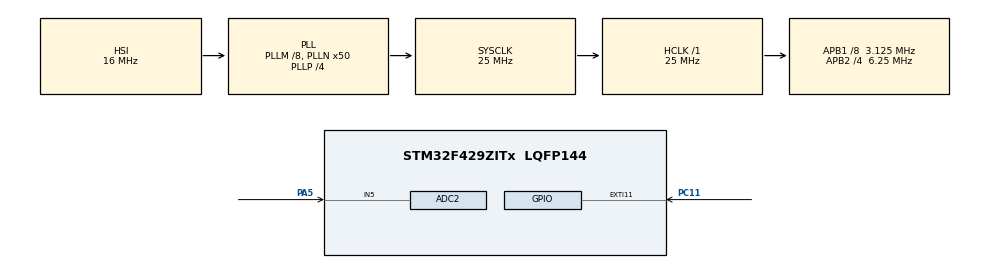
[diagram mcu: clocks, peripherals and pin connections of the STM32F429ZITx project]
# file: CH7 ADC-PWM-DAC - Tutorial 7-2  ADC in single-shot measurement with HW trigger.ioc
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ADC2.Channel-0\#ChannelRegularConversion=ADC_CHANNEL_5
ADC2.NbrOfConversionFlag=1
ADC2.Rank-0\#ChannelRegularConversion=1
ADC2.SamplingTime-0\#ChannelRegularConversion=ADC_SAMPLETIME_3CYCLES
Mcu.Family=STM32F4
Mcu.Name=STM32F429ZITx
Mcu.Package=LQFP144
NVIC.PriorityGroup=NVIC_PRIORITYGROUP_0
PA5.Signal=ADCx_IN5
PC11.Signal=GPXTI11
ProjectManager.HeapSize=0x200
ProjectManager.StackSize=0x400
ProjectManager.TargetToolchain=STM32CubeIDE
RCC.48MHZClocksFreq_Value=14285714.285714285
RCC.AHBFreq_Value=25000000
RCC.APB1CLKDivider=RCC_HCLK_DIV8
RCC.APB1Freq_Value=3125000
RCC.APB1TimFreq_Value=6250000
RCC.APB2CLKDivider=RCC_HCLK_DIV4
RCC.APB2Freq_Value=6250000
RCC.APB2TimFreq_Value=12500000
RCC.CortexFreq_Value=25000000
RCC.HCLKFreq_Value=25000000
RCC.HSE_VALUE=8000000
RCC.HSI_VALUE=16000000
RCC.LSE_VALUE=32768
RCC.PLLM=8
RCC.PLLN=50
RCC.PLLP=RCC_PLLP_DIV4
RCC.PLLQ=7
RCC.SYSCLKFreq_VALUE=25000000
RCC.SYSCLKSource=RCC_SYSCLKSOURCE_PLLCLK
RCC.VCOOutputFreq_Value=100000000
SH.ADCx_IN5.0=ADC2_IN5,IN5
board=STM32F429I-DISC1

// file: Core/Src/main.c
/* USER CODE BEGIN Header */
/**
  ******************************************************************************
  * @file           : main.c
  * @brief          : Main program body
  ******************************************************************************
  * @attention
  *
  * Copyright (c) 2024 STMicroelectronics.
  * All rights reserved.
  *
  * This software is licensed under terms that can be found in the LICENSE file
  * in the root directory of this software component.
  * If no LICENSE file comes with this software, it is provided AS-IS.
  *
  ******************************************************************************
  */
	/***************************** Tutorial Tags ******************************
	 ADC Single shot measurement
	 Hardware trigger EXTI line
	 **************************************************************************/

	/* 7.4.1 ADC Usage C Language: ******************************************
	* Tutorial 7-2: Usage of the ADC module with external channel in single-shot mode with hardware
	trigger, the C code
	*

    In this tutorial, we aims to familiarize with the external ADC channels
    and hardware triggers. To do so, we
	should connect a 10 k potentiometer between ground, VDD, and PA5 pins of the
	STM32F4 board. Also, we should connect an external push button in active high
	pull-down configuration to pin PC11. Hence, we can use it as hardware trigger.
	ADC2 will be configured as single-channel in single-shot mode and will be
	triggered with EXTI_11 line using the button connected to pin PC11.

	As the project is run, the level of the potentiometer is calculated in the
	infinite loop when the onboard button is pressed

	PS refer to Fig 7.12 of the book for circuit connections of this tutorial.

	***************************************************************************/
/* USER CODE END Header */
#include "main.h"

/* USER CODE BEGIN Includes */
#include<math.h>
/* USER CODE END Includes */

ADC_HandleTypeDef hadc2;

/* USER CODE BEGIN PV */
uint32_t ADC_val;
float Vref = 2.92, ADC_val_conv_V;
/* USER CODE END PV */

void SystemClock_Config(void);
static void MX_GPIO_Init(void);
static void MX_ADC2_Init(void);

int main(void)
{

  /* MCU Configuration--------------------------------------------------------*/

  /* Reset of all peripherals, Initializes the Flash interface and the Systick. */
  HAL_Init();

  /* Configure the system clock */
  SystemClock_Config();

  /* Initialize all configured peripherals */
  MX_GPIO_Init();
  MX_ADC2_Init();

  /* Infinite loop */
  /* USER CODE BEGIN WHILE */
  while (1)
  {
	  // Start the ADC in while loop. Every time a button is pressed the ADC wil start.
	  HAL_ADC_Start(&hadc2);

	  HAL_ADC_PollForConversion(&hadc2, 1000);
	  // Digital value
	  ADC_val = HAL_ADC_GetValue(&hadc2);
	  // Convert the ADC digital value to voltage (in V)
	  ADC_val_conv_V = (Vref/pow(2,12))*ADC_val;
	  // Delay in millisencond
	  HAL_Delay(1000);
    /* USER CODE END WHILE */

  }
}

void SystemClock_Config(void)
{
  RCC_OscInitTypeDef RCC_OscInitStruct = {0};
  RCC_ClkInitTypeDef RCC_ClkInitStruct = {0};

  /** Configure the main internal regulator output voltage
  */
  __HAL_RCC_PWR_CLK_ENABLE();
  __HAL_PWR_VOLTAGESCALING_CONFIG(PWR_REGULATOR_VOLTAGE_SCALE3);

  /** Initializes the RCC Oscillators according to the specified parameters
  * in the RCC_OscInitTypeDef structure.
  */
  RCC_OscInitStruct.OscillatorType = RCC_OSCILLATORTYPE_HSI;
  RCC_OscInitStruct.HSIState = RCC_HSI_ON;
  RCC_OscInitStruct.HSICalibrationValue = RCC_HSICALIBRATION_DEFAULT;
  RCC_OscInitStruct.PLL.PLLState = RCC_PLL_ON;
  RCC_OscInitStruct.PLL.PLLSource = RCC_PLLSOURCE_HSI;
  RCC_OscInitStruct.PLL.PLLM = 8;
  RCC_OscInitStruct.PLL.PLLN = 50;
  RCC_OscInitStruct.PLL.PLLP = RCC_PLLP_DIV4;
  RCC_OscInitStruct.PLL.PLLQ = 7;
  if (HAL_RCC_OscConfig(&RCC_OscInitStruct) != HAL_OK)
  {
    Error_Handler();
  }

  /** Initializes the CPU, AHB and APB buses clocks
  */
  RCC_ClkInitStruct.ClockType = RCC_CLOCKTYPE_HCLK|RCC_CLOCKTYPE_SYSCLK
                              |RCC_CLOCKTYPE_PCLK1|RCC_CLOCKTYPE_PCLK2;
  RCC_ClkInitStruct.SYSCLKSource = RCC_SYSCLKSOURCE_PLLCLK;
  RCC_ClkInitStruct.AHBCLKDivider = RCC_SYSCLK_DIV1;
  RCC_ClkInitStruct.APB1CLKDivider = RCC_HCLK_DIV8;
  RCC_ClkInitStruct.APB2CLKDivider = RCC_HCLK_DIV4;

  if (HAL_RCC_ClockConfig(&RCC_ClkInitStruct, FLASH_LATENCY_0) != HAL_OK)
  {
    Error_Handler();
  }
}

static void MX_ADC2_Init(void)
{

  ADC_ChannelConfTypeDef sConfig = {0};

  /** Configure the global features of the ADC (Clock, Resolution, Data Alignment and number of conversion)
  */
  hadc2.Instance = ADC2;
  hadc2.Init.ClockPrescaler = ADC_CLOCK_SYNC_PCLK_DIV2;
  hadc2.Init.Resolution = ADC_RESOLUTION_12B;
  hadc2.Init.ScanConvMode = DISABLE;
  hadc2.Init.ContinuousConvMode = DISABLE;
  hadc2.Init.DiscontinuousConvMode = DISABLE;
  hadc2.Init.ExternalTrigConvEdge = ADC_EXTERNALTRIGCONVEDGE_RISING;
  hadc2.Init.ExternalTrigConv = ADC_EXTERNALTRIGCONV_Ext_IT11;
  hadc2.Init.DataAlign = ADC_DATAALIGN_RIGHT;
  hadc2.Init.NbrOfConversion = 1;
  hadc2.Init.DMAContinuousRequests = DISABLE;
  hadc2.Init.EOCSelection = ADC_EOC_SINGLE_CONV;
  if (HAL_ADC_Init(&hadc2) != HAL_OK)
  {
    Error_Handler();
  }

  /** Configure for the selected ADC regular channel its corresponding rank in the sequencer and its sample time.
  */
  sConfig.Channel = ADC_CHANNEL_5;
  sConfig.Rank = 1;
  sConfig.SamplingTime = ADC_SAMPLETIME_3CYCLES;
  if (HAL_ADC_ConfigChannel(&hadc2, &sConfig) != HAL_OK)
  {
    Error_Handler();
  }

}

static void MX_GPIO_Init(void)
{
  GPIO_InitTypeDef GPIO_InitStruct = {0};

  /* GPIO Ports Clock Enable */
  __HAL_RCC_GPIOA_CLK_ENABLE();
  __HAL_RCC_GPIOC_CLK_ENABLE();

  /*Configure GPIO pin : PC11 */
  GPIO_InitStruct.Pin = GPIO_PIN_11;
  GPIO_InitStruct.Mode = GPIO_MODE_IT_RISING;
  GPIO_InitStruct.Pull = GPIO_NOPULL;
  HAL_GPIO_Init(GPIOC, &GPIO_InitStruct);

}

void Error_Handler(void)
{
  __disable_irq();
  while (1)
  {
  }
}
